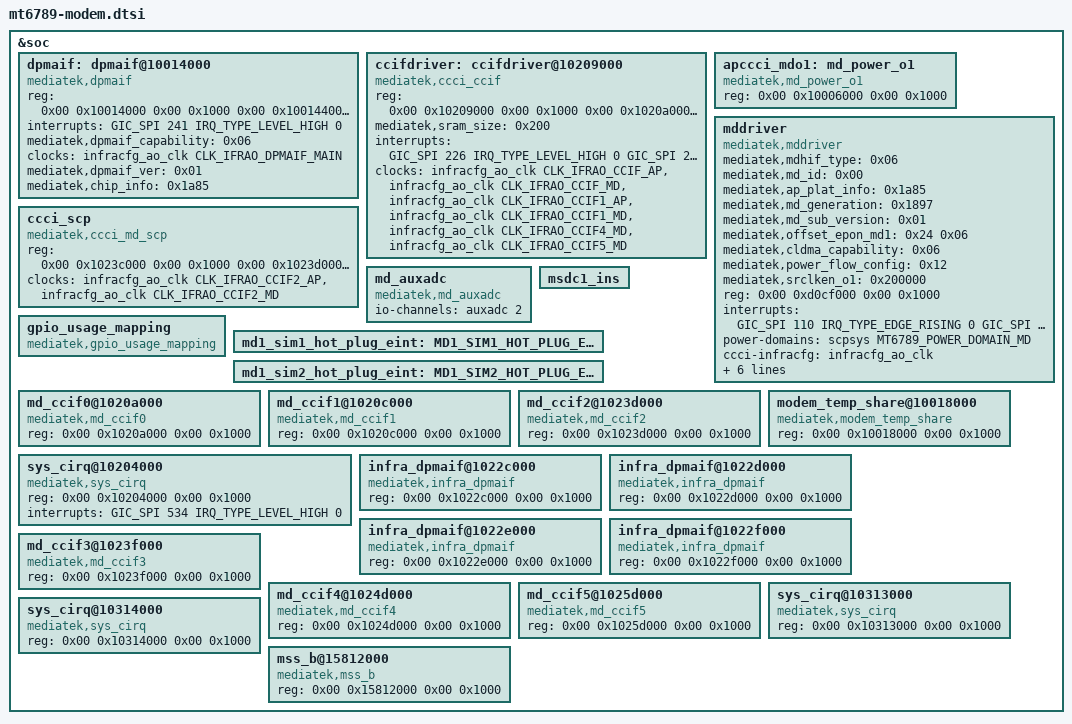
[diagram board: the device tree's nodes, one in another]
// SPDX-License-Identifier: (GPL-2.0 OR MIT)
/* MT6789 modem blocks - split out of the soc node by tools/scripts/dts-socsplit.py */

&soc {
	dpmaif: dpmaif@10014000 {
		compatible = "mediatek,dpmaif";
		reg = <0x00 0x10014000 0x00 0x1000 0x00 0x10014400 0x00 0x1000 0x00 0x1022d000 0x00 0x1000 0x00 0x1022d100 0x00 0x1000 0x00 0x1022d400 0x00 0x1000 0x00 0x1022c000 0x00 0x1000 0x00 0x1022e000 0x00 0x1000>;
		interrupts = <GIC_SPI 241 IRQ_TYPE_LEVEL_HIGH 0>;
		mediatek,dpmaif_capability = <0x06>;
		clocks = <&infracfg_ao_clk CLK_IFRAO_DPMAIF_MAIN>;
		clock-names = "infra-dpmaif-clk";
		mediatek,dpmaif_ver = <0x01>;
		mediatek,chip_info = <0x1a85>;
	};

	ccifdriver: ccifdriver@10209000 {
		compatible = "mediatek,ccci_ccif";
		reg = <0x00 0x10209000 0x00 0x1000 0x00 0x1020a000 0x00 0x1000>;
		mediatek,sram_size = <0x200>;
		interrupts = <GIC_SPI 226 IRQ_TYPE_LEVEL_HIGH 0 GIC_SPI 227 IRQ_TYPE_LEVEL_HIGH 0>;
		clocks = <&infracfg_ao_clk CLK_IFRAO_CCIF_AP &infracfg_ao_clk CLK_IFRAO_CCIF_MD &infracfg_ao_clk CLK_IFRAO_CCIF1_AP &infracfg_ao_clk CLK_IFRAO_CCIF1_MD &infracfg_ao_clk CLK_IFRAO_CCIF4_MD &infracfg_ao_clk CLK_IFRAO_CCIF5_MD>;
		clock-names = "infra-ccif-ap", "infra-ccif-md", "infra-ccif1-ap", "infra-ccif1-md", "infra-ccif4-md", "infra-ccif5-md";
	};

	apccci_mdo1: md_power_o1 {
		compatible = "mediatek,md_power_o1", "syscon";
		reg = <0x00 0x10006000 0x00 0x1000>;
	};

	mddriver: mddriver {
		compatible = "mediatek,mddriver";
		mediatek,mdhif_type = <0x06>;
		mediatek,md_id = <0x00>;
		mediatek,ap_plat_info = <0x1a85>;
		mediatek,md_generation = <0x1897>;
		mediatek,md_sub_version = <0x01>;
		mediatek,offset_epon_md1 = <0x24 0x06>;
		mediatek,cldma_capability = <0x06>;
		mediatek,power_flow_config = <0x12>;
		mediatek,srclken_o1 = <0x200000>;
		reg = <0x00 0xd0cf000 0x00 0x1000>;
		interrupts = <GIC_SPI 110 IRQ_TYPE_EDGE_RISING 0 GIC_SPI 226 IRQ_TYPE_LEVEL_HIGH 0 GIC_SPI 227 IRQ_TYPE_LEVEL_HIGH 0>;
		power-domains = <&scpsys MT6789_POWER_DOMAIN_MD>;
		ccci-infracfg = <&infracfg_ao_clk>;
		ccci-topckgen = <&topckgen_clk>;
		ccci_spmsleep = <&apccci_mdo1>;
		md_vmodem-supply = <&mt6358_vmodem_reg>;
		md_vmodem = <0xc96a8 0xc96a8>;
		md_vsram-supply = <&mt6358_vsram_core_reg>;
		md_vsram = <0xc96a8 0xc96a8>;
	};

	ccci_scp: ccci_scp {
		compatible = "mediatek,ccci_md_scp";
		reg = <0x00 0x1023c000 0x00 0x1000 0x00 0x1023d000 0x00 0x1000>;
		clocks = <&infracfg_ao_clk CLK_IFRAO_CCIF2_AP &infracfg_ao_clk CLK_IFRAO_CCIF2_MD>;
		clock-names = "infra-ccif2-ap", "infra-ccif2-md";
	};

	md_auxadc: md_auxadc {
		compatible = "mediatek,md_auxadc";
		io-channels = <&auxadc 2>;
		io-channel-names = "md-channel";
	};

	gpio_usage_mapping: gpio_usage_mapping {
		compatible = "mediatek,gpio_usage_mapping";
	};

	msdc1_ins: msdc1_ins {
	};

	md1_sim1_hot_plug_eint: MD1_SIM1_HOT_PLUG_EINT {
	};

	md1_sim2_hot_plug_eint: MD1_SIM2_HOT_PLUG_EINT {
	};

	md_ccif0@1020a000 {
		compatible = "mediatek,md_ccif0";
		reg = <0x00 0x1020a000 0x00 0x1000>;
	};

	md_ccif1@1020c000 {
		compatible = "mediatek,md_ccif1";
		reg = <0x00 0x1020c000 0x00 0x1000>;
	};

	md_ccif2@1023d000 {
		compatible = "mediatek,md_ccif2";
		reg = <0x00 0x1023d000 0x00 0x1000>;
	};

	modem_temp_share@10018000 {
		compatible = "mediatek,modem_temp_share";
		reg = <0x00 0x10018000 0x00 0x1000>;
	};

	sys_cirq@10204000 {
		compatible = "mediatek,sys_cirq";
		reg = <0x00 0x10204000 0x00 0x1000>;
		interrupts = <GIC_SPI 534 IRQ_TYPE_LEVEL_HIGH 0>;
	};

	infra_dpmaif@1022c000 {
		compatible = "mediatek,infra_dpmaif";
		reg = <0x00 0x1022c000 0x00 0x1000>;
	};

	infra_dpmaif@1022d000 {
		compatible = "mediatek,infra_dpmaif";
		reg = <0x00 0x1022d000 0x00 0x1000>;
	};

	infra_dpmaif@1022e000 {
		compatible = "mediatek,infra_dpmaif";
		reg = <0x00 0x1022e000 0x00 0x1000>;
	};

	infra_dpmaif@1022f000 {
		compatible = "mediatek,infra_dpmaif";
		reg = <0x00 0x1022f000 0x00 0x1000>;
	};

	md_ccif3@1023f000 {
		compatible = "mediatek,md_ccif3";
		reg = <0x00 0x1023f000 0x00 0x1000>;
	};

	md_ccif4@1024d000 {
		compatible = "mediatek,md_ccif4";
		reg = <0x00 0x1024d000 0x00 0x1000>;
	};

	md_ccif5@1025d000 {
		compatible = "mediatek,md_ccif5";
		reg = <0x00 0x1025d000 0x00 0x1000>;
	};

	sys_cirq@10313000 {
		compatible = "mediatek,sys_cirq";
		reg = <0x00 0x10313000 0x00 0x1000>;
	};

	sys_cirq@10314000 {
		compatible = "mediatek,sys_cirq";
		reg = <0x00 0x10314000 0x00 0x1000>;
	};

	mss_b@15812000 {
		compatible = "mediatek,mss_b";
		reg = <0x00 0x15812000 0x00 0x1000>;
	};

};
